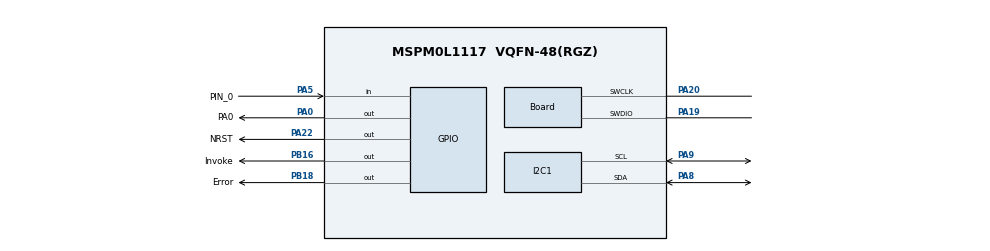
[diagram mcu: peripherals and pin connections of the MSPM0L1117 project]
// @cliArgs --device "MSPM0L111X" --package "VQFN-48(RGZ)" --part "Default"
// @v2CliArgs --device "MSPM0L1117" --package "VQFN-48(RGZ)"
// @cliArgs --board /ti/boards/LP_MSPM0L1117 --rtos nortos

/**
 * Import the modules used in this configuration.
 */
const GPIO   = scripting.addModule("/ti/driverlib/GPIO", {}, false);
const GPIO1  = GPIO.addInstance();
const GPIO2  = GPIO.addInstance();
const GPIO3  = GPIO.addInstance();
const I2C    = scripting.addModule("/ti/driverlib/I2C", {}, false);
const I2C1   = I2C.addInstance();
const SYSCTL = scripting.addModule("/ti/driverlib/SYSCTL");

/**
 * Write custom configuration values to the imported modules.
 */
GPIO1.$name                              = "GPIO_Button";
GPIO1.associatedPins[0].$name            = "PIN_0";
GPIO1.associatedPins[0].direction        = "INPUT";
GPIO1.associatedPins[0].internalResistor = "PULL_UP";
GPIO1.associatedPins[0].assignedPort     = "PORTA";
GPIO1.associatedPins[0].assignedPin      = "5";
GPIO1.associatedPins[0].pin.$assign      = "PA5";

const Board                       = scripting.addModule("/ti/driverlib/Board", {}, false);
Board.peripheral.$assign          = "DEBUGSS";
Board.peripheral.swclkPin.$assign = "PA20";
Board.peripheral.swdioPin.$assign = "PA19";

GPIO2.$name                          = "GPIO_BSL";
GPIO2.associatedPins.create(2);
GPIO2.associatedPins[0].$name        = "NRST";
GPIO2.associatedPins[0].initialValue = "SET";
GPIO2.associatedPins[0].assignedPort = "PORTA";
GPIO2.associatedPins[0].assignedPin  = "22";
GPIO2.associatedPins[0].pin.$assign  = "PA22";
GPIO2.associatedPins[1].$name        = "Invoke";
GPIO2.associatedPins[1].assignedPort = "PORTB";
GPIO2.associatedPins[1].assignedPin  = "16";
GPIO2.associatedPins[1].pin.$assign  = "PB16";

GPIO3.$name                          = "GPIO_LED";
GPIO3.associatedPins.create(2);
GPIO3.associatedPins[0].$name        = "Error";
GPIO3.associatedPins[0].assignedPort = "PORTB";
GPIO3.associatedPins[0].assignedPin  = "18";
GPIO3.associatedPins[0].pin.$assign  = "PB18";
GPIO3.associatedPins[1].$name        = "PA0";
GPIO3.associatedPins[1].initialValue = "SET";
GPIO3.associatedPins[1].assignedPort = "PORTA";
GPIO3.associatedPins[1].assignedPin  = "0";
GPIO3.associatedPins[1].pin.$assign  = "PA0";

I2C1.$name                     = "I2C_0";
I2C1.basicEnableController     = true;
I2C1.enableTimeoutA            = true;
I2C1.timeoutACount             = 255;
I2C1.peripheral.$assign        = "I2C0";
I2C1.peripheral.sdaPin.$assign = "PA8";
I2C1.peripheral.sclPin.$assign = "PA9";

SYSCTL.peripheral.$assign = "SYSCTL";

const ProjectConfig              = scripting.addModule("/ti/project_config/ProjectConfig", {}, false);
ProjectConfig.migrationCondition = true;
